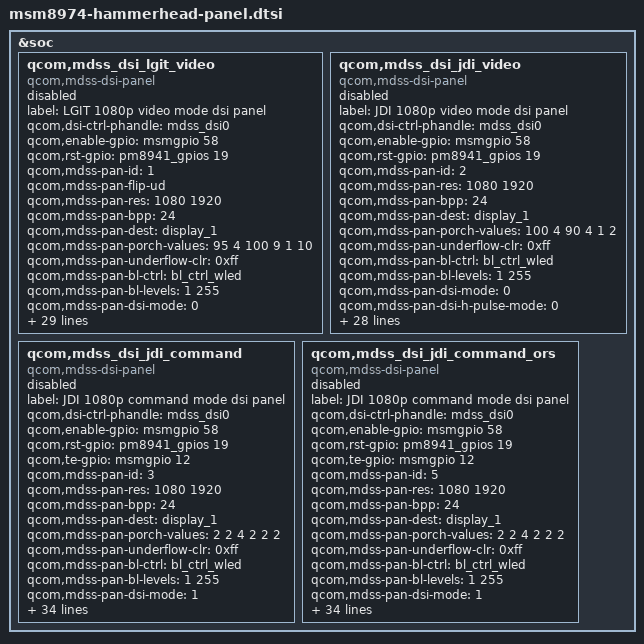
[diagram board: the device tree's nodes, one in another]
/* Copyright (c) 2012, Code Aurora Forum. All rights reserved.
 *
 * This program is free software; you can redistribute it and/or modify
 * it under the terms of the GNU General Public License version 2 and
 * only version 2 as published by the Free Software Foundation.
 *
 * This program is distributed in the hope that it will be useful,
 * but WITHOUT ANY WARRANTY; without even the implied warranty of
 * MERCHANTABILITY or FITNESS FOR A PARTICULAR PURPOSE.  See the
 * GNU General Public License for more details.
 */

&soc {
	qcom,mdss_dsi_lgit_video {
		compatible = "qcom,mdss-dsi-panel";
		label = "LGIT 1080p video mode dsi panel";
		status = "disable";
		qcom,dsi-ctrl-phandle = <&mdss_dsi0>;
		qcom,enable-gpio = <&msmgpio 58 0>;
		qcom,rst-gpio = <&pm8941_gpios 19 0>;
		qcom,mdss-pan-id = <1>;
		qcom,mdss-pan-flip-ud;
		qcom,mdss-pan-res = <1080 1920>;
		qcom,mdss-pan-bpp = <24>;
		qcom,mdss-pan-dest = "display_1";
		qcom,mdss-pan-porch-values = <95 4 100 9 1 10>;
		qcom,mdss-pan-underflow-clr = <0xff>;
		qcom,mdss-pan-bl-ctrl = "bl_ctrl_wled";
		qcom,mdss-pan-bl-levels = <1 255>;
		qcom,mdss-pan-dsi-mode = <0>;
		qcom,mdss-pan-dsi-h-pulse-mode = <0>;
		qcom,mdss-pan-dsi-h-power-stop = <0 0 0>;
		qcom,mdss-pan-dsi-bllp-power-stop = <1 1>;
		qcom,mdss-pan-dsi-traffic-mode = <1>;
		qcom,mdss-pan-dsi-dst-format = <3>;
		qcom,mdss-pan-dsi-vc = <0>;
		qcom,mdss-pan-dsi-rgb-swap = <0>;
		qcom,mdss-pan-dsi-data-lanes = <1 1 1 1>;
		qcom,mdss-pan-dsi-dlane-swap = <0>;
		qcom,mdss-pan-dsi-t-clk = <0x22 0x36>;
		qcom,mdss-pan-dsi-stream = <0>;
		qcom,mdss-pan-dsi-mdp-tr = <0x0>;
		qcom,mdss-pan-dsi-dma-tr = <0x04>;
		qcom,mdss-pan-dsi-frame-rate = <60>;
		qcom,mdss-pan-clk-rate = <899000000>;
		qcom,panel-phy-regulatorSettings = [
			03 01 01 00  /* Regualotor settings */
			20 00 01];
		qcom,panel-phy-timingSettings = [
			E5 38 26 00 69 72
			2B 3B 41 03 04 00];
		qcom,panel-phy-strengthCtrl = [
			77 06];
		qcom,panel-phy-bistCtrl = [
			00 00 b1 ff           /* BIST Ctrl settings */
			00 00];
		qcom,panel-phy-laneConfig = [
			00 c2 45 00 00 00 00 01 75 /* lane0 config */
			00 c2 45 00 00 00 00 01 75 /* lane1 config */
			00 c2 45 00 00 00 00 01 75 /* lane2 config */
			00 c2 45 00 00 00 00 01 75 /* lane3 config */
			00 02 45 00 00 00 00 01 97]; /* Clk ln config */
		qcom,panel-on-cmds = [
			29 01 00 00 00 00 02 b0 04  // changed it to 29
			05 01 00 00 00 00 02 00 00
			05 01 00 00 00 00 02 00 00
			29 01 00 00 00 00 07 b3
			14 00 00 00 00 00
			29 01 00 00 00 00 03 b6
			3a d3
			29 01 00 00 00 00 23 c1
			84 60 50 00 00 00
			00 00 00 0c 01 58
			73 ae 31 20 06 00
			00 00 00 00 00 10
			10 10 10 00 00 00
			22 02 02 00
			29 01 00 00 00 00 08 c2
			30 f7 80 0a 08 00
			00
			29 01 00 00 00 00 17 c4
			70 00 00 00 00 04
			00 00 00 11 06 00
			00 00 00 00 04 00
			00 00 11 06
			29 01 00 00 00 00 29 c6
			06 6d 06 6d 06 6d
			00 00 00 00 06 6d
			06 6d 06 6d 15 19
			07 00 01 06 6d 06
			6d 06 6d 00 00 00
			00 06 6d 06 6d 06
			6d 15 19 07
			29 01 00 00 00 00 19 c7
			00 09 14 26 32 49
			3b 52 5f 67 6b 70
			00 09 14 26 32 49
			3b 52 5f 67 6b 70
			29 01 00 00 00 00 19 c8
			00 09 14 26 32 49
			3b 52 5f 67 6b 70
			00 09 14 26 32 49
			3b 52 5f 67 6b 70
			29 01 00 00 00 00 19 c9
			00 09 14 26 32 49
			3b 52 5f 67 6b 70
			00 09 14 26 32 49
			3b 52 5f 67 6b 70
			29 01 00 00 00 00 02 cc 09
			29 01 00 00 00 00 0f d0
			00 00 19 18 99 99
			19 01 89 00 55 19
			99 01
			29 01 00 00 00 00 1b d3
			1b 33 bb cc c4 33
			33 33 00 01 00 a0
			d8 a0 0d 37 33 44
			22 70 02 37 03 3d
			bf 00
			29 01 00 00 00 00 08 d5
			06 00 00 01 4a 01
			4a
			29 01 00 00 00 00 08 // Changed it to 15
			d5 06 00 00 01 4a
			01 4a
			15 01 00 00 00 00 02 36 C0

			05 01 00 00 00 00 02 29 00
			05 01 00 00 78 00 02 11 00];
		qcom,on-cmds-dsi-state = "DSI_LP_MODE";
		qcom,panel-off-cmds = [
			05 01 00 00 14 00 02 28 00
			05 01 00 00 64 00 02 10 00];
		qcom,off-cmds-dsi-state = "DSI_HS_MODE";
	};

	qcom,mdss_dsi_jdi_video {
		compatible = "qcom,mdss-dsi-panel";
		label = "JDI 1080p video mode dsi panel";
		status = "disable";
		qcom,dsi-ctrl-phandle = <&mdss_dsi0>;
		qcom,enable-gpio = <&msmgpio 58 0>;
		qcom,rst-gpio = <&pm8941_gpios 19 0>;
		qcom,mdss-pan-id = <2>;
		qcom,mdss-pan-res = <1080 1920>;
		qcom,mdss-pan-bpp = <24>;
		qcom,mdss-pan-dest = "display_1";
		qcom,mdss-pan-porch-values = <100 4 90 4 1 2>;
		qcom,mdss-pan-underflow-clr = <0xff>;
		qcom,mdss-pan-bl-ctrl = "bl_ctrl_wled";
		qcom,mdss-pan-bl-levels = <1 255>;
		qcom,mdss-pan-dsi-mode = <0>;
		qcom,mdss-pan-dsi-h-pulse-mode = <0>;
		qcom,mdss-pan-dsi-h-power-stop = <0 0 0>;
		qcom,mdss-pan-dsi-bllp-power-stop = <1 1>;
		qcom,mdss-pan-dsi-traffic-mode = <1>;
		qcom,mdss-pan-dsi-dst-format = <3>;
		qcom,mdss-pan-dsi-vc = <0>;
		qcom,mdss-pan-dsi-rgb-swap = <0>;
		qcom,mdss-pan-dsi-data-lanes = <1 1 1 1>;
		qcom,mdss-pan-dsi-dlane-swap = <0>;
		qcom,mdss-pan-dsi-t-clk = <0x2C 0x0A>;
		qcom,mdss-pan-dsi-stream = <0>;
		qcom,mdss-pan-dsi-mdp-tr = <0x0>;
		qcom,mdss-pan-dsi-dma-tr = <0x04>;
		qcom,mdss-pan-dsi-frame-rate = <53>;
		qcom,mdss-pan-clk-rate = <780689360>;
		qcom,panel-phy-regulatorSettings = [
			03 01 01 00  /* Regualotor settings */
			20 00 01];
		qcom,panel-phy-timingSettings = [
			cc 31 21 00 5f 68
			26 34 50 03 04 00];
		qcom,panel-phy-strengthCtrl = [
			77 06];
		qcom,panel-phy-bistCtrl = [
			00 00 b1 ff 		  /* BIST Ctrl settings */
			00 00];
		qcom,panel-phy-laneConfig = [
			00 c2 45 00 00 00 00 01 75 /* lane0 config */
			00 c2 45 00 00 00 00 01 75 /* lane1 config */
			00 c2 45 00 00 00 00 01 75 /* lane2 config */
			00 c2 45 00 00 00 00 01 75 /* lane3 config */
			00 02 45 00 00 00 00 01 97]; /* Clk ln config */
		qcom,panel-on-cmds = [
			15 01 00 00 00 00 02 ff 10
			15 01 00 00 00 00 02 bb 03
			39 01 00 00 00 00 06
			3b 03 04 02 64 5A
			15 01 00 00 00 00 02 50 00
			15 01 00 00 00 00 02 ff 20
			15 01 00 00 00 00 02 75 00
			15 01 00 00 00 00 02 76 00
			15 01 00 00 00 00 02 77 00
			15 01 00 00 00 00 02 78 16
			15 01 00 00 00 00 02 79 00
			15 01 00 00 00 00 02 7a 3a
			15 01 00 00 00 00 02 7b 00
			15 01 00 00 00 00 02 7c 57
			15 01 00 00 00 00 02 7d 00
			15 01 00 00 00 00 02 7e 6f
			15 01 00 00 00 00 02 7f 00
			15 01 00 00 00 00 02 80 83
			15 01 00 00 00 00 02 81 00
			15 01 00 00 00 00 02 82 94
			15 01 00 00 00 00 02 83 00
			15 01 00 00 00 00 02 84 a3
			15 01 00 00 00 00 02 85 00
			15 01 00 00 00 00 02 86 b0
			15 01 00 00 00 00 02 87 00
			15 01 00 00 00 00 02 88 de
			15 01 00 00 00 00 02 89 01
			15 01 00 00 00 00 02 8a 04
			15 01 00 00 00 00 02 8b 01
			15 01 00 00 00 00 02 8c 3e
			15 01 00 00 00 00 02 8d 01
			15 01 00 00 00 00 02 8e 6d
			15 01 00 00 00 00 02 8f 01
			15 01 00 00 00 00 02 90 b5
			15 01 00 00 00 00 02 91 01
			15 01 00 00 00 00 02 92 ee
			15 01 00 00 00 00 02 93 01
			15 01 00 00 00 00 02 94 f0
			15 01 00 00 00 00 02 95 02
			15 01 00 00 00 00 02 96 24
			15 01 00 00 00 00 02 97 02
			15 01 00 00 00 00 02 98 5b
			15 01 00 00 00 00 02 99 02
			15 01 00 00 00 00 02 9a 7d
			15 01 00 00 00 00 02 9b 02
			15 01 00 00 00 00 02 9c a9
			15 01 00 00 00 00 02 9d 02
			15 01 00 00 00 00 02 9e c4
			15 01 00 00 00 00 02 9f 02
			15 01 00 00 00 00 02 a0 e7
			15 01 00 00 00 00 02 a2 02
			15 01 00 00 00 00 02 a3 f1
			15 01 00 00 00 00 02 a4 02
			15 01 00 00 00 00 02 a5 f5
			15 01 00 00 00 00 02 a6 03
			15 01 00 00 00 00 02 a7 04
			15 01 00 00 00 00 02 a9 03
			15 01 00 00 00 00 02 aa 0c
			15 01 00 00 00 00 02 ab 03
			15 01 00 00 00 00 02 ac 1e
			15 01 00 00 00 00 02 ad 03
			15 01 00 00 00 00 02 ae 47
			15 01 00 00 00 00 02 af 03
			15 01 00 00 00 00 02 b0 b9
			15 01 00 00 00 00 02 b1 03
			15 01 00 00 00 00 02 b2 ff
			15 01 00 00 00 00 02 b3 00
			15 01 00 00 00 00 02 b4 00
			15 01 00 00 00 00 02 b5 00
			15 01 00 00 00 00 02 b6 16
			15 01 00 00 00 00 02 b7 00
			15 01 00 00 00 00 02 b8 3a
			15 01 00 00 00 00 02 b9 00
			15 01 00 00 00 00 02 ba 57
			15 01 00 00 00 00 02 bb 00
			15 01 00 00 00 00 02 bc 6f
			15 01 00 00 00 00 02 bd 00
			15 01 00 00 00 00 02 be 83
			15 01 00 00 00 00 02 bf 00
			15 01 00 00 00 00 02 c0 94
			15 01 00 00 00 00 02 c1 00
			15 01 00 00 00 00 02 c2 a3
			15 01 00 00 00 00 02 c3 00
			15 01 00 00 00 00 02 c4 b0
			15 01 00 00 00 00 02 c5 00
			15 01 00 00 00 00 02 c6 de
			15 01 00 00 00 00 02 c7 01
			15 01 00 00 00 00 02 c8 04
			15 01 00 00 00 00 02 c9 01
			15 01 00 00 00 00 02 ca 3e
			15 01 00 00 00 00 02 cb 01
			15 01 00 00 00 00 02 cc 6d
			15 01 00 00 00 00 02 cd 01
			15 01 00 00 00 00 02 ce b5
			15 01 00 00 00 00 02 cf 01
			15 01 00 00 00 00 02 d0 ee
			15 01 00 00 00 00 02 d1 01
			15 01 00 00 00 00 02 d2 f0
			15 01 00 00 00 00 02 d3 02
			15 01 00 00 00 00 02 d4 24
			15 01 00 00 00 00 02 d5 02
			15 01 00 00 00 00 02 d6 5b
			15 01 00 00 00 00 02 d7 02
			15 01 00 00 00 00 02 d8 7d
			15 01 00 00 00 00 02 d9 02
			15 01 00 00 00 00 02 da a9
			15 01 00 00 00 00 02 db 02
			15 01 00 00 00 00 02 dc c4
			15 01 00 00 00 00 02 dd 02
			15 01 00 00 00 00 02 de e7
			15 01 00 00 00 00 02 df 02
			15 01 00 00 00 00 02 e0 f1
			15 01 00 00 00 00 02 e1 02
			15 01 00 00 00 00 02 e2 f5
			15 01 00 00 00 00 02 e3 03
			15 01 00 00 00 00 02 e4 04
			15 01 00 00 00 00 02 e5 03
			15 01 00 00 00 00 02 e6 0c
			15 01 00 00 00 00 02 e7 03
			15 01 00 00 00 00 02 e8 1e
			15 01 00 00 00 00 02 e9 03
			15 01 00 00 00 00 02 ea 47
			15 01 00 00 00 00 02 eb 03
			15 01 00 00 00 00 02 ec b9
			15 01 00 00 00 00 02 ed 03
			15 01 00 00 00 00 02 ee ff
			15 01 00 00 00 00 02 ef 00
			15 01 00 00 00 00 02 f0 6d
			15 01 00 00 00 00 02 f1 00
			15 01 00 00 00 00 02 f2 77
			15 01 00 00 00 00 02 f3 00
			15 01 00 00 00 00 02 f4 89
			15 01 00 00 00 00 02 f5 00
			15 01 00 00 00 00 02 f6 9a
			15 01 00 00 00 00 02 f7 00
			15 01 00 00 00 00 02 f8 a9
			15 01 00 00 00 00 02 f9 00
			15 01 00 00 00 00 02 fa b7
			15 01 00 00 00 00 02 fb 01
			15 01 00 00 00 00 02 ff 21
			15 01 00 00 00 00 02 00 00
			15 01 00 00 00 00 02 01 c3
			15 01 00 00 00 00 02 02 00
			15 01 00 00 00 00 02 03 cf
			15 01 00 00 00 00 02 04 00
			15 01 00 00 00 00 02 05 d9
			15 01 00 00 00 00 02 06 00
			15 01 00 00 00 00 02 07 ff
			15 01 00 00 00 00 02 08 01
			15 01 00 00 00 00 02 09 1f
			15 01 00 00 00 00 02 0a 01
			15 01 00 00 00 00 02 0b 53
			15 01 00 00 00 00 02 0c 01
			15 01 00 00 00 00 02 0d 7d
			15 01 00 00 00 00 02 0e 01
			15 01 00 00 00 00 02 0f c1
			15 01 00 00 00 00 02 10 01
			15 01 00 00 00 00 02 11 f8
			15 01 00 00 00 00 02 12 01
			15 01 00 00 00 00 02 13 fa
			15 01 00 00 00 00 02 14 02
			15 01 00 00 00 00 02 15 2c
			15 01 00 00 00 00 02 16 02
			15 01 00 00 00 00 02 17 61
			15 01 00 00 00 00 02 18 02
			15 01 00 00 00 00 02 19 82
			15 01 00 00 00 00 02 1a 02
			15 01 00 00 00 00 02 1b ad
			15 01 00 00 00 00 02 1c 02
			15 01 00 00 00 00 02 1d c8
			15 01 00 00 00 00 02 1e 02
			15 01 00 00 00 00 02 1f e8
			15 01 00 00 00 00 02 20 02
			15 01 00 00 00 00 02 21 f5
			15 01 00 00 00 00 02 22 02
			15 01 00 00 00 00 02 23 f8
			15 01 00 00 00 00 02 24 03
			15 01 00 00 00 00 02 25 06
			15 01 00 00 00 00 02 26 03
			15 01 00 00 00 00 02 27 0f
			15 01 00 00 00 00 02 28 03
			15 01 00 00 00 00 02 29 1d
			15 01 00 00 00 00 02 2a 03
			15 01 00 00 00 00 02 2b 3f
			15 01 00 00 00 00 02 2d 03
			15 01 00 00 00 00 02 2f ba
			15 01 00 00 00 00 02 30 03
			15 01 00 00 00 00 02 31 ff
			15 01 00 00 00 00 02 32 00
			15 01 00 00 00 00 02 33 6d
			15 01 00 00 00 00 02 34 00
			15 01 00 00 00 00 02 35 77
			15 01 00 00 00 00 02 36 00
			15 01 00 00 00 00 02 37 89
			15 01 00 00 00 00 02 38 00
			15 01 00 00 00 00 02 39 9a
			15 01 00 00 00 00 02 3a 00
			15 01 00 00 00 00 02 3b a9
			15 01 00 00 00 00 02 3d 00
			15 01 00 00 00 00 02 3f b7
			15 01 00 00 00 00 02 40 00
			15 01 00 00 00 00 02 41 c3
			15 01 00 00 00 00 02 42 00
			15 01 00 00 00 00 02 43 cf
			15 01 00 00 00 00 02 44 00
			15 01 00 00 00 00 02 45 d9
			15 01 00 00 00 00 02 46 00
			15 01 00 00 00 00 02 47 ff
			15 01 00 00 00 00 02 48 01
			15 01 00 00 00 00 02 49 1f
			15 01 00 00 00 00 02 4a 01
			15 01 00 00 00 00 02 4b 53
			15 01 00 00 00 00 02 4c 01
			15 01 00 00 00 00 02 4d 7d
			15 01 00 00 00 00 02 4e 01
			15 01 00 00 00 00 02 4f c1
			15 01 00 00 00 00 02 50 01
			15 01 00 00 00 00 02 51 f8
			15 01 00 00 00 00 02 52 01
			15 01 00 00 00 00 02 53 fa
			15 01 00 00 00 00 02 54 02
			15 01 00 00 00 00 02 55 2c
			15 01 00 00 00 00 02 56 02
			15 01 00 00 00 00 02 58 61
			15 01 00 00 00 00 02 59 02
			15 01 00 00 00 00 02 5a 82
			15 01 00 00 00 00 02 5b 02
			15 01 00 00 00 00 02 5c ad
			15 01 00 00 00 00 02 5d 02
			15 01 00 00 00 00 02 5e c8
			15 01 00 00 00 00 02 5f 02
			15 01 00 00 00 00 02 60 e8
			15 01 00 00 00 00 02 61 02
			15 01 00 00 00 00 02 62 f5
			15 01 00 00 00 00 02 63 02
			15 01 00 00 00 00 02 64 f8
			15 01 00 00 00 00 02 65 03
			15 01 00 00 00 00 02 66 06
			15 01 00 00 00 00 02 67 03
			15 01 00 00 00 00 02 68 0f
			15 01 00 00 00 00 02 69 03
			15 01 00 00 00 00 02 6a 1d
			15 01 00 00 00 00 02 6b 03
			15 01 00 00 00 00 02 6c 3f
			15 01 00 00 00 00 02 6d 03
			15 01 00 00 00 00 02 6e ba
			15 01 00 00 00 00 02 6f 03
			15 01 00 00 00 00 02 70 ff
			15 01 00 00 00 00 02 71 00
			15 01 00 00 00 00 02 72 a8
			15 01 00 00 00 00 02 73 00
			15 01 00 00 00 00 02 74 af
			15 01 00 00 00 00 02 75 00
			15 01 00 00 00 00 02 76 bc
			15 01 00 00 00 00 02 77 00
			15 01 00 00 00 00 02 78 c9
			15 01 00 00 00 00 02 79 00
			15 01 00 00 00 00 02 7a d4
			15 01 00 00 00 00 02 7b 00
			15 01 00 00 00 00 02 7c de
			15 01 00 00 00 00 02 7d 00
			15 01 00 00 00 00 02 7e e7
			15 01 00 00 00 00 02 7f 00
			15 01 00 00 00 00 02 80 f0
			15 01 00 00 00 00 02 81 00
			15 01 00 00 00 00 02 82 f9
			15 01 00 00 00 00 02 83 01
			15 01 00 00 00 00 02 84 17
			15 01 00 00 00 00 02 85 01
			15 01 00 00 00 00 02 86 32
			15 01 00 00 00 00 02 87 01
			15 01 00 00 00 00 02 88 5f
			15 01 00 00 00 00 02 89 01
			15 01 00 00 00 00 02 8a 86
			15 01 00 00 00 00 02 8b 01
			15 01 00 00 00 00 02 8c c5
			15 01 00 00 00 00 02 8d 01
			15 01 00 00 00 00 02 8e f9
			15 01 00 00 00 00 02 8f 01
			15 01 00 00 00 00 02 90 fb
			15 01 00 00 00 00 02 91 02
			15 01 00 00 00 00 02 92 2d
			15 01 00 00 00 00 02 93 02
			15 01 00 00 00 00 02 94 62
			15 01 00 00 00 00 02 95 02
			15 01 00 00 00 00 02 96 83
			15 01 00 00 00 00 02 97 02
			15 01 00 00 00 00 02 98 af
			15 01 00 00 00 00 02 99 02
			15 01 00 00 00 00 02 9a c8
			15 01 00 00 00 00 02 9b 02
			15 01 00 00 00 00 02 9c ee
			15 01 00 00 00 00 02 9d 02
			15 01 00 00 00 00 02 9e f9
			15 01 00 00 00 00 02 9f 02
			15 01 00 00 00 00 02 a0 fd
			15 01 00 00 00 00 02 a2 03
			15 01 00 00 00 00 02 a3 0e
			15 01 00 00 00 00 02 a4 03
			15 01 00 00 00 00 02 a5 15
			15 01 00 00 00 00 02 a6 03
			15 01 00 00 00 00 02 a7 25
			15 01 00 00 00 00 02 a9 03
			15 01 00 00 00 00 02 aa 44
			15 01 00 00 00 00 02 ab 03
			15 01 00 00 00 00 02 ac bb
			15 01 00 00 00 00 02 ad 03
			15 01 00 00 00 00 02 ae ff
			15 01 00 00 00 00 02 af 00
			15 01 00 00 00 00 02 b0 a8
			15 01 00 00 00 00 02 b1 00
			15 01 00 00 00 00 02 b2 af
			15 01 00 00 00 00 02 b3 00
			15 01 00 00 00 00 02 b4 bc
			15 01 00 00 00 00 02 b5 00
			15 01 00 00 00 00 02 b6 c9
			15 01 00 00 00 00 02 b7 00
			15 01 00 00 00 00 02 b8 d4
			15 01 00 00 00 00 02 b9 00
			15 01 00 00 00 00 02 ba de
			15 01 00 00 00 00 02 bb 00
			15 01 00 00 00 00 02 bc e7
			15 01 00 00 00 00 02 bd 00
			15 01 00 00 00 00 02 be f0
			15 01 00 00 00 00 02 bf 00
			15 01 00 00 00 00 02 c0 f9
			15 01 00 00 00 00 02 c1 01
			15 01 00 00 00 00 02 c2 17
			15 01 00 00 00 00 02 c3 01
			15 01 00 00 00 00 02 c4 32
			15 01 00 00 00 00 02 c5 01
			15 01 00 00 00 00 02 c6 5f
			15 01 00 00 00 00 02 c7 01
			15 01 00 00 00 00 02 c8 86
			15 01 00 00 00 00 02 c9 01
			15 01 00 00 00 00 02 ca c5
			15 01 00 00 00 00 02 cb 01
			15 01 00 00 00 00 02 cc f9
			15 01 00 00 00 00 02 cd 01
			15 01 00 00 00 00 02 ce fb
			15 01 00 00 00 00 02 cf 02
			15 01 00 00 00 00 02 d0 2d
			15 01 00 00 00 00 02 d1 02
			15 01 00 00 00 00 02 d2 62
			15 01 00 00 00 00 02 d3 02
			15 01 00 00 00 00 02 d4 83
			15 01 00 00 00 00 02 d5 02
			15 01 00 00 00 00 02 d6 af
			15 01 00 00 00 00 02 d7 02
			15 01 00 00 00 00 02 d8 c8
			15 01 00 00 00 00 02 d9 02
			15 01 00 00 00 00 02 da ee
			15 01 00 00 00 00 02 db 02
			15 01 00 00 00 00 02 dc f9
			15 01 00 00 00 00 02 dd 02
			15 01 00 00 00 00 02 de fd
			15 01 00 00 00 00 02 df 03
			15 01 00 00 00 00 02 e0 0e
			15 01 00 00 00 00 02 e1 03
			15 01 00 00 00 00 02 e2 15
			15 01 00 00 00 00 02 e3 03
			15 01 00 00 00 00 02 e4 25
			15 01 00 00 00 00 02 e5 03
			15 01 00 00 00 00 02 e6 44
			15 01 00 00 00 00 02 e7 03
			15 01 00 00 00 00 02 e8 bb
			15 01 00 00 00 00 02 e9 03
			15 01 00 00 00 00 02 ea ff
			15 01 00 00 00 00 02 eb 30
			15 01 00 00 00 00 02 ec 17
			15 01 00 00 00 00 02 ed 20
			15 01 00 00 00 00 02 ee 0f
			15 01 00 00 00 00 02 ef 1f
			15 01 00 00 00 00 02 f0 0f
			15 01 00 00 00 00 02 f1 0f
			15 01 00 00 00 00 02 f2 07
			15 01 00 00 00 00 02 fb 01
			15 01 00 00 00 00 02 ff f0
			15 01 00 00 00 00 02 15 01
			15 01 00 00 00 00 02 fb 01
			15 01 00 00 00 00 02 FF 28 // For adjust TP
			15 01 00 00 00 00 02 58 40 // For adjust TP
			15 01 00 00 00 00 02 FB 01 // For adjust TP
			15 01 00 00 00 00 02 ff f0//added in revA
			15 01 00 00 00 00 02 15 01//added in revA
			15 01 00 00 00 00 02 fb 01//added in revA
			15 01 00 00 00 00 02 ff e0
			15 01 00 00 00 00 02 b8 3d
			15 01 00 00 00 00 02 fb 01
			15 01 00 00 00 00 02 ff 10
			15 01 00 00 00 00 02 35 00
			39 01 00 00 00 00 05
			2a 00 00 04 37
			39 01 00 00 00 00 05
			2b 00 00 07 7f
			05 01 00 00 78 00 01 11
			05 01 00 00 00 00 01 29];
		qcom,on-cmds-dsi-state = "DSI_LP_MODE";
		qcom,panel-off-cmds = [
			15 01 00 00 00 00 02 ff 10
			05 01 00 00 32 00 01 28
			05 01 00 00 64 00 01 10];
		qcom,off-cmds-dsi-state = "DSI_HS_MODE";
	};

	qcom,mdss_dsi_jdi_command {
		compatible = "qcom,mdss-dsi-panel";
		label = "JDI 1080p command mode dsi panel";
		status = "disable";
		qcom,dsi-ctrl-phandle = <&mdss_dsi0>;
		qcom,enable-gpio = <&msmgpio 58 0>;
		qcom,rst-gpio = <&pm8941_gpios 19 0>;
		qcom,te-gpio = <&msmgpio 12 0>;
		qcom,mdss-pan-id = <3>;
		qcom,mdss-pan-res = <1080 1920>;
		qcom,mdss-pan-bpp = <24>;
		qcom,mdss-pan-dest = "display_1";
		qcom,mdss-pan-porch-values = <2 2 4 2 2 2>;
		qcom,mdss-pan-underflow-clr = <0xff>;
		qcom,mdss-pan-bl-ctrl = "bl_ctrl_wled";
		qcom,mdss-pan-bl-levels = <1 255>;
		qcom,mdss-pan-dsi-mode = <1>;
		qcom,mdss-vsync-enable = <1>;
		qcom,mdss-hw-vsync-mode = <1>;
		qcom,mdss-pan-dsi-h-pulse-mode = <0>;
		qcom,mdss-pan-dsi-h-power-stop = <0 0 0>;
		qcom,mdss-pan-dsi-bllp-power-stop = <1 1>;
		qcom,mdss-pan-dsi-traffic-mode = <1>;
		qcom,mdss-pan-dsi-dst-format = <8>;
		qcom,mdss-pan-dsi-vc = <0>;
		qcom,mdss-pan-dsi-rgb-swap = <0>;
		qcom,mdss-pan-dsi-data-lanes = <1 1 1 1>;
		qcom,mdss-pan-dsi-dlane-swap = <0>;
		qcom,mdss-pan-dsi-t-clk = <0x51 0x30>;
		qcom,mdss-pan-dsi-stream = <0>;
		qcom,mdss-pan-dsi-mdp-tr = <0x0>;
		qcom,mdss-pan-dsi-dma-tr = <0x04>;
		qcom,mdss-pan-dsi-frame-rate = <60>;
		qcom,mdss-pan-te-sel = <1>;
		qcom,mdss-pan-wr-mem-continue = <0x3c>;
		qcom,mdss-pan-wr-mem-start = <0x2c>;
		qcom,mdss-pan-insert-dcs-cmd = <1>;
		qcom,panel-phy-regulatorSettings = [
			03 01 01 00  /* Regualotor settings */
			20 00 01];
		qcom,panel-phy-timingSettings = [
			ad 3c 2f 00 54 4e
			31 3e 4c 03 04 00];
		qcom,panel-phy-strengthCtrl = [
			77 06];
		qcom,panel-phy-bistCtrl = [
			00 00 b1 ff           /* BIST Ctrl settings */
			00 00];
		qcom,panel-phy-laneConfig = [
			00 c2 45 00 00 00 00 01 75 /* lane0 config */
			00 c2 45 00 00 00 00 01 75 /* lane1 config */
			00 c2 45 00 00 00 00 01 75 /* lane2 config */
			00 c2 45 00 00 00 00 01 75 /* lane3 config */
			00 02 45 00 00 00 00 01 97]; /* Clk ln config */
		qcom,panel-on-cmds = [
			15 01 00 00 00 00 02 ff 10
			15 01 00 00 00 00 02 bb 10
			15 01 00 00 00 00 02 50 00
			15 01 00 00 00 00 02 ff 20
			15 01 00 00 00 00 02 75 00
			15 01 00 00 00 00 02 76 00
			15 01 00 00 00 00 02 77 00
			15 01 00 00 00 00 02 78 16
			15 01 00 00 00 00 02 79 00
			15 01 00 00 00 00 02 7a 3a
			15 01 00 00 00 00 02 7b 00
			15 01 00 00 00 00 02 7c 57
			15 01 00 00 00 00 02 7d 00
			15 01 00 00 00 00 02 7e 6f
			15 01 00 00 00 00 02 7f 00
			15 01 00 00 00 00 02 80 83
			15 01 00 00 00 00 02 81 00
			15 01 00 00 00 00 02 82 94
			15 01 00 00 00 00 02 83 00
			15 01 00 00 00 00 02 84 a3
			15 01 00 00 00 00 02 85 00
			15 01 00 00 00 00 02 86 b0
			15 01 00 00 00 00 02 87 00
			15 01 00 00 00 00 02 88 de
			15 01 00 00 00 00 02 89 01
			15 01 00 00 00 00 02 8a 04
			15 01 00 00 00 00 02 8b 01
			15 01 00 00 00 00 02 8c 3e
			15 01 00 00 00 00 02 8d 01
			15 01 00 00 00 00 02 8e 6d
			15 01 00 00 00 00 02 8f 01
			15 01 00 00 00 00 02 90 b5
			15 01 00 00 00 00 02 91 01
			15 01 00 00 00 00 02 92 ee
			15 01 00 00 00 00 02 93 01
			15 01 00 00 00 00 02 94 f0
			15 01 00 00 00 00 02 95 02
			15 01 00 00 00 00 02 96 24
			15 01 00 00 00 00 02 97 02
			15 01 00 00 00 00 02 98 5b
			15 01 00 00 00 00 02 99 02
			15 01 00 00 00 00 02 9a 7d
			15 01 00 00 00 00 02 9b 02
			15 01 00 00 00 00 02 9c a9
			15 01 00 00 00 00 02 9d 02
			15 01 00 00 00 00 02 9e c4
			15 01 00 00 00 00 02 9f 02
			15 01 00 00 00 00 02 a0 e7
			15 01 00 00 00 00 02 a2 02
			15 01 00 00 00 00 02 a3 f1
			15 01 00 00 00 00 02 a4 02
			15 01 00 00 00 00 02 a5 f5
			15 01 00 00 00 00 02 a6 03
			15 01 00 00 00 00 02 a7 04
			15 01 00 00 00 00 02 a9 03
			15 01 00 00 00 00 02 aa 0c
			15 01 00 00 00 00 02 ab 03
			15 01 00 00 00 00 02 ac 1e
			15 01 00 00 00 00 02 ad 03
			15 01 00 00 00 00 02 ae 47
			15 01 00 00 00 00 02 af 03
			15 01 00 00 00 00 02 b0 b9
			15 01 00 00 00 00 02 b1 03
			15 01 00 00 00 00 02 b2 ff
			15 01 00 00 00 00 02 b3 00
			15 01 00 00 00 00 02 b4 00
			15 01 00 00 00 00 02 b5 00
			15 01 00 00 00 00 02 b6 16
			15 01 00 00 00 00 02 b7 00
			15 01 00 00 00 00 02 b8 3a
			15 01 00 00 00 00 02 b9 00
			15 01 00 00 00 00 02 ba 57
			15 01 00 00 00 00 02 bb 00
			15 01 00 00 00 00 02 bc 6f
			15 01 00 00 00 00 02 bd 00
			15 01 00 00 00 00 02 be 83
			15 01 00 00 00 00 02 bf 00
			15 01 00 00 00 00 02 c0 94
			15 01 00 00 00 00 02 c1 00
			15 01 00 00 00 00 02 c2 a3
			15 01 00 00 00 00 02 c3 00
			15 01 00 00 00 00 02 c4 b0
			15 01 00 00 00 00 02 c5 00
			15 01 00 00 00 00 02 c6 de
			15 01 00 00 00 00 02 c7 01
			15 01 00 00 00 00 02 c8 04
			15 01 00 00 00 00 02 c9 01
			15 01 00 00 00 00 02 ca 3e
			15 01 00 00 00 00 02 cb 01
			15 01 00 00 00 00 02 cc 6d
			15 01 00 00 00 00 02 cd 01
			15 01 00 00 00 00 02 ce b5
			15 01 00 00 00 00 02 cf 01
			15 01 00 00 00 00 02 d0 ee
			15 01 00 00 00 00 02 d1 01
			15 01 00 00 00 00 02 d2 f0
			15 01 00 00 00 00 02 d3 02
			15 01 00 00 00 00 02 d4 24
			15 01 00 00 00 00 02 d5 02
			15 01 00 00 00 00 02 d6 5b
			15 01 00 00 00 00 02 d7 02
			15 01 00 00 00 00 02 d8 7d
			15 01 00 00 00 00 02 d9 02
			15 01 00 00 00 00 02 da a9
			15 01 00 00 00 00 02 db 02
			15 01 00 00 00 00 02 dc c4
			15 01 00 00 00 00 02 dd 02
			15 01 00 00 00 00 02 de e7
			15 01 00 00 00 00 02 df 02
			15 01 00 00 00 00 02 e0 f1
			15 01 00 00 00 00 02 e1 02
			15 01 00 00 00 00 02 e2 f5
			15 01 00 00 00 00 02 e3 03
			15 01 00 00 00 00 02 e4 04
			15 01 00 00 00 00 02 e5 03
			15 01 00 00 00 00 02 e6 0c
			15 01 00 00 00 00 02 e7 03
			15 01 00 00 00 00 02 e8 1e
			15 01 00 00 00 00 02 e9 03
			15 01 00 00 00 00 02 ea 47
			15 01 00 00 00 00 02 eb 03
			15 01 00 00 00 00 02 ec b9
			15 01 00 00 00 00 02 ed 03
			15 01 00 00 00 00 02 ee ff
			15 01 00 00 00 00 02 ef 00
			15 01 00 00 00 00 02 f0 6d
			15 01 00 00 00 00 02 f1 00
			15 01 00 00 00 00 02 f2 77
			15 01 00 00 00 00 02 f3 00
			15 01 00 00 00 00 02 f4 89
			15 01 00 00 00 00 02 f5 00
			15 01 00 00 00 00 02 f6 9a
			15 01 00 00 00 00 02 f7 00
			15 01 00 00 00 00 02 f8 a9
			15 01 00 00 00 00 02 f9 00
			15 01 00 00 00 00 02 fa b7
			15 01 00 00 00 00 02 fb 01
			15 01 00 00 00 00 02 ff 21
			15 01 00 00 00 00 02 00 00
			15 01 00 00 00 00 02 01 c3
			15 01 00 00 00 00 02 02 00
			15 01 00 00 00 00 02 03 cf
			15 01 00 00 00 00 02 04 00
			15 01 00 00 00 00 02 05 d9
			15 01 00 00 00 00 02 06 00
			15 01 00 00 00 00 02 07 ff
			15 01 00 00 00 00 02 08 01
			15 01 00 00 00 00 02 09 1f
			15 01 00 00 00 00 02 0a 01
			15 01 00 00 00 00 02 0b 53
			15 01 00 00 00 00 02 0c 01
			15 01 00 00 00 00 02 0d 7d
			15 01 00 00 00 00 02 0e 01
			15 01 00 00 00 00 02 0f c1
			15 01 00 00 00 00 02 10 01
			15 01 00 00 00 00 02 11 f8
			15 01 00 00 00 00 02 12 01
			15 01 00 00 00 00 02 13 fa
			15 01 00 00 00 00 02 14 02
			15 01 00 00 00 00 02 15 2c
			15 01 00 00 00 00 02 16 02
			15 01 00 00 00 00 02 17 61
			15 01 00 00 00 00 02 18 02
			15 01 00 00 00 00 02 19 82
			15 01 00 00 00 00 02 1a 02
			15 01 00 00 00 00 02 1b ad
			15 01 00 00 00 00 02 1c 02
			15 01 00 00 00 00 02 1d c8
			15 01 00 00 00 00 02 1e 02
			15 01 00 00 00 00 02 1f e8
			15 01 00 00 00 00 02 20 02
			15 01 00 00 00 00 02 21 f5
			15 01 00 00 00 00 02 22 02
			15 01 00 00 00 00 02 23 f8
			15 01 00 00 00 00 02 24 03
			15 01 00 00 00 00 02 25 06
			15 01 00 00 00 00 02 26 03
			15 01 00 00 00 00 02 27 0f
			15 01 00 00 00 00 02 28 03
			15 01 00 00 00 00 02 29 1d
			15 01 00 00 00 00 02 2a 03
			15 01 00 00 00 00 02 2b 3f
			15 01 00 00 00 00 02 2d 03
			15 01 00 00 00 00 02 2f ba
			15 01 00 00 00 00 02 30 03
			15 01 00 00 00 00 02 31 ff
			15 01 00 00 00 00 02 32 00
			15 01 00 00 00 00 02 33 6d
			15 01 00 00 00 00 02 34 00
			15 01 00 00 00 00 02 35 77
			15 01 00 00 00 00 02 36 00
			15 01 00 00 00 00 02 37 89
			15 01 00 00 00 00 02 38 00
			15 01 00 00 00 00 02 39 9a
			15 01 00 00 00 00 02 3a 00
			15 01 00 00 00 00 02 3b a9
			15 01 00 00 00 00 02 3d 00
			15 01 00 00 00 00 02 3f b7
			15 01 00 00 00 00 02 40 00
			15 01 00 00 00 00 02 41 c3
			15 01 00 00 00 00 02 42 00
			15 01 00 00 00 00 02 43 cf
			15 01 00 00 00 00 02 44 00
			15 01 00 00 00 00 02 45 d9
			15 01 00 00 00 00 02 46 00
			15 01 00 00 00 00 02 47 ff
			15 01 00 00 00 00 02 48 01
			15 01 00 00 00 00 02 49 1f
			15 01 00 00 00 00 02 4a 01
			15 01 00 00 00 00 02 4b 53
			15 01 00 00 00 00 02 4c 01
			15 01 00 00 00 00 02 4d 7d
			15 01 00 00 00 00 02 4e 01
			15 01 00 00 00 00 02 4f c1
			15 01 00 00 00 00 02 50 01
			15 01 00 00 00 00 02 51 f8
			15 01 00 00 00 00 02 52 01
			15 01 00 00 00 00 02 53 fa
			15 01 00 00 00 00 02 54 02
			15 01 00 00 00 00 02 55 2c
			15 01 00 00 00 00 02 56 02
			15 01 00 00 00 00 02 58 61
			15 01 00 00 00 00 02 59 02
			15 01 00 00 00 00 02 5a 82
			15 01 00 00 00 00 02 5b 02
			15 01 00 00 00 00 02 5c ad
			15 01 00 00 00 00 02 5d 02
			15 01 00 00 00 00 02 5e c8
			15 01 00 00 00 00 02 5f 02
			15 01 00 00 00 00 02 60 e8
			15 01 00 00 00 00 02 61 02
			15 01 00 00 00 00 02 62 f5
			15 01 00 00 00 00 02 63 02
			15 01 00 00 00 00 02 64 f8
			15 01 00 00 00 00 02 65 03
			15 01 00 00 00 00 02 66 06
			15 01 00 00 00 00 02 67 03
			15 01 00 00 00 00 02 68 0f
			15 01 00 00 00 00 02 69 03
			15 01 00 00 00 00 02 6a 1d
			15 01 00 00 00 00 02 6b 03
			15 01 00 00 00 00 02 6c 3f
			15 01 00 00 00 00 02 6d 03
			15 01 00 00 00 00 02 6e ba
			15 01 00 00 00 00 02 6f 03
			15 01 00 00 00 00 02 70 ff
			15 01 00 00 00 00 02 71 00
			15 01 00 00 00 00 02 72 a8
			15 01 00 00 00 00 02 73 00
			15 01 00 00 00 00 02 74 af
			15 01 00 00 00 00 02 75 00
			15 01 00 00 00 00 02 76 bc
			15 01 00 00 00 00 02 77 00
			15 01 00 00 00 00 02 78 c9
			15 01 00 00 00 00 02 79 00
			15 01 00 00 00 00 02 7a d4
			15 01 00 00 00 00 02 7b 00
			15 01 00 00 00 00 02 7c de
			15 01 00 00 00 00 02 7d 00
			15 01 00 00 00 00 02 7e e7
			15 01 00 00 00 00 02 7f 00
			15 01 00 00 00 00 02 80 f0
			15 01 00 00 00 00 02 81 00
			15 01 00 00 00 00 02 82 f9
			15 01 00 00 00 00 02 83 01
			15 01 00 00 00 00 02 84 17
			15 01 00 00 00 00 02 85 01
			15 01 00 00 00 00 02 86 32
			15 01 00 00 00 00 02 87 01
			15 01 00 00 00 00 02 88 5f
			15 01 00 00 00 00 02 89 01
			15 01 00 00 00 00 02 8a 86
			15 01 00 00 00 00 02 8b 01
			15 01 00 00 00 00 02 8c c5
			15 01 00 00 00 00 02 8d 01
			15 01 00 00 00 00 02 8e f9
			15 01 00 00 00 00 02 8f 01
			15 01 00 00 00 00 02 90 fb
			15 01 00 00 00 00 02 91 02
			15 01 00 00 00 00 02 92 2d
			15 01 00 00 00 00 02 93 02
			15 01 00 00 00 00 02 94 62
			15 01 00 00 00 00 02 95 02
			15 01 00 00 00 00 02 96 83
			15 01 00 00 00 00 02 97 02
			15 01 00 00 00 00 02 98 af
			15 01 00 00 00 00 02 99 02
			15 01 00 00 00 00 02 9a c8
			15 01 00 00 00 00 02 9b 02
			15 01 00 00 00 00 02 9c ee
			15 01 00 00 00 00 02 9d 02
			15 01 00 00 00 00 02 9e f9
			15 01 00 00 00 00 02 9f 02
			15 01 00 00 00 00 02 a0 fd
			15 01 00 00 00 00 02 a2 03
			15 01 00 00 00 00 02 a3 0e
			15 01 00 00 00 00 02 a4 03
			15 01 00 00 00 00 02 a5 15
			15 01 00 00 00 00 02 a6 03
			15 01 00 00 00 00 02 a7 25
			15 01 00 00 00 00 02 a9 03
			15 01 00 00 00 00 02 aa 44
			15 01 00 00 00 00 02 ab 03
			15 01 00 00 00 00 02 ac bb
			15 01 00 00 00 00 02 ad 03
			15 01 00 00 00 00 02 ae ff
			15 01 00 00 00 00 02 af 00
			15 01 00 00 00 00 02 b0 a8
			15 01 00 00 00 00 02 b1 00
			15 01 00 00 00 00 02 b2 af
			15 01 00 00 00 00 02 b3 00
			15 01 00 00 00 00 02 b4 bc
			15 01 00 00 00 00 02 b5 00
			15 01 00 00 00 00 02 b6 c9
			15 01 00 00 00 00 02 b7 00
			15 01 00 00 00 00 02 b8 d4
			15 01 00 00 00 00 02 b9 00
			15 01 00 00 00 00 02 ba de
			15 01 00 00 00 00 02 bb 00
			15 01 00 00 00 00 02 bc e7
			15 01 00 00 00 00 02 bd 00
			15 01 00 00 00 00 02 be f0
			15 01 00 00 00 00 02 bf 00
			15 01 00 00 00 00 02 c0 f9
			15 01 00 00 00 00 02 c1 01
			15 01 00 00 00 00 02 c2 17
			15 01 00 00 00 00 02 c3 01
			15 01 00 00 00 00 02 c4 32
			15 01 00 00 00 00 02 c5 01
			15 01 00 00 00 00 02 c6 5f
			15 01 00 00 00 00 02 c7 01
			15 01 00 00 00 00 02 c8 86
			15 01 00 00 00 00 02 c9 01
			15 01 00 00 00 00 02 ca c5
			15 01 00 00 00 00 02 cb 01
			15 01 00 00 00 00 02 cc f9
			15 01 00 00 00 00 02 cd 01
			15 01 00 00 00 00 02 ce fb
			15 01 00 00 00 00 02 cf 02
			15 01 00 00 00 00 02 d0 2d
			15 01 00 00 00 00 02 d1 02
			15 01 00 00 00 00 02 d2 62
			15 01 00 00 00 00 02 d3 02
			15 01 00 00 00 00 02 d4 83
			15 01 00 00 00 00 02 d5 02
			15 01 00 00 00 00 02 d6 af
			15 01 00 00 00 00 02 d7 02
			15 01 00 00 00 00 02 d8 c8
			15 01 00 00 00 00 02 d9 02
			15 01 00 00 00 00 02 da ee
			15 01 00 00 00 00 02 db 02
			15 01 00 00 00 00 02 dc f9
			15 01 00 00 00 00 02 dd 02
			15 01 00 00 00 00 02 de fd
			15 01 00 00 00 00 02 df 03
			15 01 00 00 00 00 02 e0 0e
			15 01 00 00 00 00 02 e1 03
			15 01 00 00 00 00 02 e2 15
			15 01 00 00 00 00 02 e3 03
			15 01 00 00 00 00 02 e4 25
			15 01 00 00 00 00 02 e5 03
			15 01 00 00 00 00 02 e6 44
			15 01 00 00 00 00 02 e7 03
			15 01 00 00 00 00 02 e8 bb
			15 01 00 00 00 00 02 e9 03
			15 01 00 00 00 00 02 ea ff
			15 01 00 00 00 00 02 eb 30
			15 01 00 00 00 00 02 ec 17
			15 01 00 00 00 00 02 ed 20
			15 01 00 00 00 00 02 ee 0f
			15 01 00 00 00 00 02 ef 1f
			15 01 00 00 00 00 02 f0 0f
			15 01 00 00 00 00 02 f1 0f
			15 01 00 00 00 00 02 f2 07
			15 01 00 00 00 00 02 fb 01
			15 01 00 00 00 00 02 ff f0
			15 01 00 00 00 00 02 15 01
			15 01 00 00 00 00 02 fb 01
			15 01 00 00 00 00 02 FF 28 // For adjust TP
			15 01 00 00 00 00 02 58 40 // For adjust TP
			15 01 00 00 00 00 02 FB 01 // For adjust TP
			15 01 00 00 00 00 02 ff f0 // added in revA
			15 01 00 00 00 00 02 15 01 // added in revA
			15 01 00 00 00 00 02 fb 01 // added in revA
			15 01 00 00 00 00 02 ff e0
			15 01 00 00 00 00 02 b8 3d
			15 01 00 00 00 00 02 fb 01
			15 01 00 00 00 00 02 ff 10
			15 01 00 00 00 00 02 35 00
			39 01 00 00 00 00 05
			2a 00 00 04 37
			39 01 00 00 00 00 05
			2b 00 00 07 7f
			05 01 00 00 78 00 01 11
			05 01 00 00 00 00 01 29];
		qcom,on-cmds-dsi-state = "DSI_LP_MODE";
		qcom,panel-off-cmds = [
			15 01 00 00 00 00 00 02 ff 10
			05 01 00 00 32 00 01 28
			05 01 00 00 64 00 01 10];
		qcom,off-cmds-dsi-state = "DSI_HS_MODE";
	};

	qcom,mdss_dsi_jdi_command_ors {
		compatible = "qcom,mdss-dsi-panel";
		label = "JDI 1080p command mode dsi panel";
		status = "disable";
		qcom,dsi-ctrl-phandle = <&mdss_dsi0>;
		qcom,enable-gpio = <&msmgpio 58 0>;
		qcom,rst-gpio = <&pm8941_gpios 19 0>;
		qcom,te-gpio = <&msmgpio 12 0>;
		qcom,mdss-pan-id = <5>;
		qcom,mdss-pan-res = <1080 1920>;
		qcom,mdss-pan-bpp = <24>;
		qcom,mdss-pan-dest = "display_1";
		qcom,mdss-pan-porch-values = <2 2 4 2 2 2>;
		qcom,mdss-pan-underflow-clr = <0xff>;
		qcom,mdss-pan-bl-ctrl = "bl_ctrl_wled";
		qcom,mdss-pan-bl-levels = <1 255>;
		qcom,mdss-pan-dsi-mode = <1>;
		qcom,mdss-vsync-enable = <1>;
		qcom,mdss-hw-vsync-mode = <1>;
		qcom,mdss-pan-dsi-h-pulse-mode = <0>;
		qcom,mdss-pan-dsi-h-power-stop = <0 0 0>;
		qcom,mdss-pan-dsi-bllp-power-stop = <1 1>;
		qcom,mdss-pan-dsi-traffic-mode = <1>;
		qcom,mdss-pan-dsi-dst-format = <8>;
		qcom,mdss-pan-dsi-vc = <0>;
		qcom,mdss-pan-dsi-rgb-swap = <0>;
		qcom,mdss-pan-dsi-data-lanes = <1 1 1 1>;
		qcom,mdss-pan-dsi-dlane-swap = <0>;
		qcom,mdss-pan-dsi-t-clk = <0x32 0x1F>;
		qcom,mdss-pan-dsi-stream = <0>;
		qcom,mdss-pan-dsi-mdp-tr = <0x0>;
		qcom,mdss-pan-dsi-dma-tr = <0x04>;
		qcom,mdss-pan-dsi-frame-rate = <60>;
		qcom,mdss-pan-te-sel = <1>;
		qcom,mdss-pan-wr-mem-continue = <0x3c>;
		qcom,mdss-pan-wr-mem-start = <0x2c>;
		qcom,mdss-pan-insert-dcs-cmd = <1>;
		qcom,panel-phy-regulatorSettings = [
			03 01 01 00  /* Regualotor settings */
			20 00 01];
		qcom,panel-phy-timingSettings = [
			ad 3c 2f 00 54 4e
			31 3e 4c 03 04 00];
		qcom,panel-phy-strengthCtrl = [
			77 06];
		qcom,panel-phy-bistCtrl = [
			00 00 b1 ff           /* BIST Ctrl settings */
			00 00];
		qcom,panel-phy-laneConfig = [
			00 c2 45 00 00 00 00 01 75 /* lane0 config */
			00 c2 45 00 00 00 00 01 75 /* lane1 config */
			00 c2 45 00 00 00 00 01 75 /* lane2 config */
			00 c2 45 00 00 00 00 01 75 /* lane3 config */
			00 02 45 00 00 00 00 01 97]; /* Clk ln config */
		qcom,panel-on-cmds = [
			15 01 00 00 00 00 02 00 00
			39 01 00 00 00 00 05
			FF 19 02 01 00
			15 01 00 00 00 00 02 00 80
			39 01 00 00 00 00 03
			FF 19 02
			15 01 00 00 00 00 02 00 00
			39 01 00 00 00 00 19
			E1 00 07 0E 18 21
			28 33 44 4F 5F 6C
			75 85 7F 79 6E 60
			54 4D 49 42 30 1E
			00
			15 01 00 00 00 00 02 00 00
			39 01 00 00 00 00 19
			E2 00 07 0E 18 21
			28 33 44 4F 5F 6C
			75 85 7F 79 6E 60
			54 4D 49 42 30 1E
			00
			15 01 00 00 00 00 02 00 00
			39 01 00 00 00 00 19
			E3 36 38 3A 3F 43
			46 4D 59 5F 6C 75
			7C 7F 7A 75 6A 5C
			51 4A 46 3F 2D 1C
			00
			15 01 00 00 00 00 02 00 00
			39 01 00 00 00 00 19
			E4 36 38 3A 3F 43
			46 4D 59 5F 6C 75
			7C 7F 7A 75 6A 5C
			51 4A 46 3F 2D 1C
			00
			15 01 00 00 00 00 02 00 00
			39 01 00 00 00 00 19
			E5 4A 4B 4C 4F 52
			5f 5A 63 66 70 78
			7D 7E 79 74 69 5B
			50 49 44 3B 29 19
			00
			15 01 00 00 00 00 02 00 00
			39 01 00 00 00 00 19
			E6 4A 4B 4C 4F 52
			55 5A 63 66 70 78
			7D 7E 79 74 69 5B
			50 49 44 3B 29 19
			00
			15 01 00 00 00 00 02 00 00
			39 01 00 00 00 00 05
			FF 19 02 01 00
			15 01 00 00 00 00 02 00 80
			39 01 00 00 00 00 03
			FF 19 02
			15 01 00 00 00 00 02 00 83
			15 01 00 00 00 00 02 F3 C2
			15 01 00 00 00 00 02 00 00
			15 01 00 00 00 00 02 35 00
			39 01 00 00 00 00 05
			2A 00 00 04 37
			39 01 00 00 00 00 05
			2B 00 00 07 7F
			05 01 00 00 78 00 01 11
			05 01 00 00 00 00 01 29];
		qcom,on-cmds-dsi-state = "DSI_LP_MODE";
		qcom,panel-off-cmds = [
			05 01 00 00 32 00 01 28
			05 01 00 00 64 00 01 10];
		qcom,off-cmds-dsi-state = "DSI_HS_MODE";
	};
};
